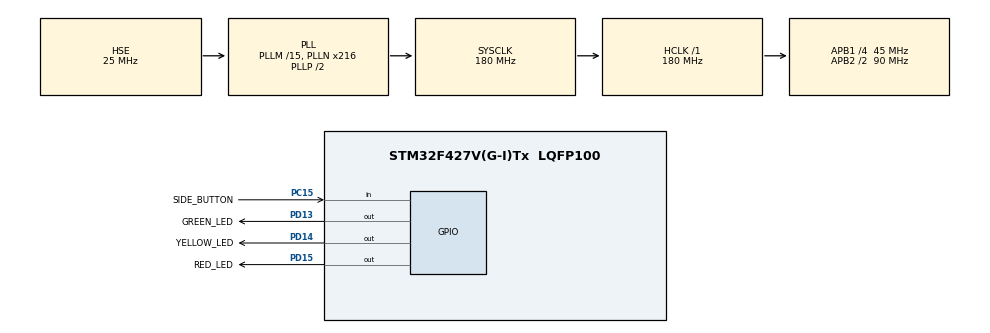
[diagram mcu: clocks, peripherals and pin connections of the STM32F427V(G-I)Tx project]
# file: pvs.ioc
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Mcu.Family=STM32F4
Mcu.Name=STM32F427V(G-I)Tx
Mcu.Package=LQFP100
NVIC.PriorityGroup=NVIC_PRIORITYGROUP_4
PC15/OSC32_OUT.GPIO_Label=SIDE_BUTTON
PC15/OSC32_OUT.Signal=GPIO_Input
PD13.GPIO_Label=GREEN_LED
PD13.Signal=GPIO_Output
PD14.GPIO_Label=YELLOW_LED
PD14.Signal=GPIO_Output
PD15.GPIO_Label=RED_LED
PD15.Signal=GPIO_Output
PH0/OSC_IN.Mode=HSE-External-Oscillator
PH0/OSC_IN.Signal=RCC_OSC_IN
PH1/OSC_OUT.Mode=HSE-External-Oscillator
PH1/OSC_OUT.Signal=RCC_OSC_OUT
ProjectManager.HeapSize=0x200
ProjectManager.StackSize=0x400
ProjectManager.TargetToolchain=STM32CubeIDE
RCC.48MHZClocksFreq_Value=90000000
RCC.AHBFreq_Value=180000000
RCC.APB1CLKDivider=RCC_HCLK_DIV4
RCC.APB1Freq_Value=45000000
RCC.APB1TimFreq_Value=90000000
RCC.APB2CLKDivider=RCC_HCLK_DIV2
RCC.APB2Freq_Value=90000000
RCC.APB2TimFreq_Value=180000000
RCC.CortexFreq_Value=180000000
RCC.HCLKFreq_Value=180000000
RCC.HSE_VALUE=25000000
RCC.HSI_VALUE=16000000
RCC.LSE_VALUE=32768
RCC.PLLM=15
RCC.PLLN=216
RCC.PLLSourceVirtual=RCC_PLLSOURCE_HSE
RCC.SYSCLKFreq_VALUE=180000000
RCC.SYSCLKSource=RCC_SYSCLKSOURCE_PLLCLK
RCC.VCOOutputFreq_Value=360000000
board=custom

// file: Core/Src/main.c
/* USER CODE BEGIN Header */
/**
  ******************************************************************************
  * @file           : main.c
  * @brief          : Main program body
  ******************************************************************************
  * @attention
  *
  * <h2><center>&copy; Copyright (c) 2022 STMicroelectronics.
  * All rights reserved.</center></h2>
  *
  * This software component is licensed by ST under BSD 3-Clause license,
  * the "License"; You may not use this file except in compliance with the
  * License. You may obtain a copy of the License at:
  *                        opensource.org/licenses/BSD-3-Clause
  *
  ******************************************************************************
  */
/* USER CODE END Header */
#include "main.h"
#include "gpio.h"

void SystemClock_Config(void);
/* USER CODE BEGIN PFP */
void set_code(uint8_t proto);
/* USER CODE END PFP */

int main(void)
{

  /* MCU Configuration--------------------------------------------------------*/

  /* Reset of all peripherals, Initializes the Flash interface and the Systick. */
  HAL_Init();

  /* Configure the system clock */
  SystemClock_Config();

  /* Initialize all configured peripherals */
  MX_GPIO_Init();

  /* Infinite loop */
  /* USER CODE BEGIN WHILE */
  int i;
  int redTime;
  bool press;
    while (1)
    {
      redTime = 4000;
      press = false;

      //green
        HAL_GPIO_TogglePin(GPIOD, GPIO_PIN_13);
        HAL_Delay(1500);

        //green light
        for(i = 0; i < 7; ++i)
        {
          HAL_GPIO_TogglePin(GPIOD, GPIO_PIN_13);
             press = waitColor(300)  press;
        }

        // yellow
        HAL_GPIO_TogglePin(GPIOD, GPIO_PIN_14);
        press = waitColor(300)  press;
        HAL_GPIO_TogglePin(GPIOD, GPIO_PIN_14);

        //red
        HAL_GPIO_TogglePin(GPIOD, GPIO_PIN_15);
        if (press) {
          redTime = 1000;
        }

        while(redTime > 0 && (HAL_GPIO_ReadPin(GPIOC, GPIO_PIN_15) != GPIO_PIN_RESET || press)){
         HAL_Delay(1);
         redTime--;
        }

        if(redTime > 3000){
         HAL_Delay(redTime-3000);
        }
        HAL_GPIO_TogglePin(GPIOD, GPIO_PIN_15);

    }
  /* USER CODE END 3 */
}

void SystemClock_Config(void)
{
  RCC_OscInitTypeDef RCC_OscInitStruct = {0};
  RCC_ClkInitTypeDef RCC_ClkInitStruct = {0};

  /** Configure the main internal regulator output voltage
  */
  __HAL_RCC_PWR_CLK_ENABLE();
  __HAL_PWR_VOLTAGESCALING_CONFIG(PWR_REGULATOR_VOLTAGE_SCALE1);
  /** Initializes the RCC Oscillators according to the specified parameters
  * in the RCC_OscInitTypeDef structure.
  */
  RCC_OscInitStruct.OscillatorType = RCC_OSCILLATORTYPE_HSE;
  RCC_OscInitStruct.HSEState = RCC_HSE_ON;
  RCC_OscInitStruct.PLL.PLLState = RCC_PLL_ON;
  RCC_OscInitStruct.PLL.PLLSource = RCC_PLLSOURCE_HSE;
  RCC_OscInitStruct.PLL.PLLM = 15;
  RCC_OscInitStruct.PLL.PLLN = 216;
  RCC_OscInitStruct.PLL.PLLP = RCC_PLLP_DIV2;
  RCC_OscInitStruct.PLL.PLLQ = 4;
  if (HAL_RCC_OscConfig(&RCC_OscInitStruct) != HAL_OK)
  {
    Error_Handler();
  }
  / Activate the Over-Drive mode
  */
  if (HAL_PWREx_EnableOverDrive() != HAL_OK)
  {
    Error_Handler();
  }
  / Initializes the CPU, AHB and APB buses clocks
  */
  RCC_ClkInitStruct.ClockType = RCC_CLOCKTYPE_HCLK|RCC_CLOCKTYPE_SYSCLK
                              |RCC_CLOCKTYPE_PCLK1|RCC_CLOCKTYPE_PCLK2;
  RCC_ClkInitStruct.SYSCLKSource = RCC_SYSCLKSOURCE_PLLCLK;
  RCC_ClkInitStruct.AHBCLKDivider = RCC_SYSCLK_DIV1;
  RCC_ClkInitStruct.APB1CLKDivider = RCC_HCLK_DIV4;
  RCC_ClkInitStruct.APB2CLKDivider = RCC_HCLK_DIV2;

  if (HAL_RCC_ClockConfig(&RCC_ClkInitStruct, FLASH_LATENCY_5) != HAL_OK)
  {
    Error_Handler();
  }
}

/* USER CODE BEGIN 4 */
bool waitColor(int time) {
  while(time > 0 && HAL_GPIO_ReadPin(GPIOC, GPIO_PIN_15) != GPIO_PIN_RESET){
       HAL_Delay(1);
       time--;
  }
  if (time != 0) {
    HAL_Delay(time);
    return true;
  }
  return false;
}
/* USER CODE END 4 */

void Error_Handler(void)
{
  __disable_irq();
  while (1)
  {
  }
}

/************************ (C) COPYRIGHT STMicroelectronics *****END OF FILE****/
